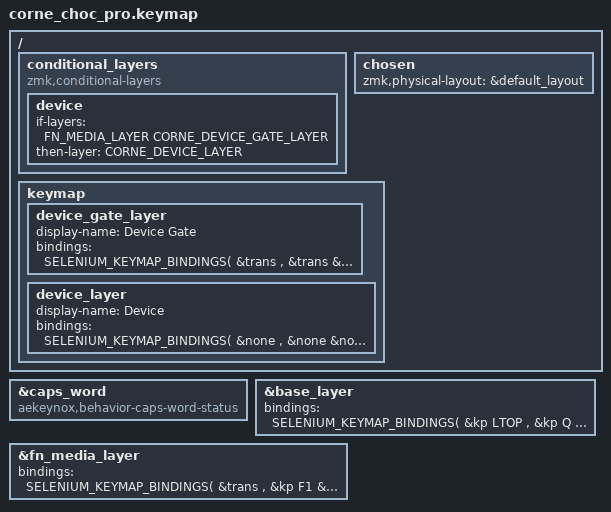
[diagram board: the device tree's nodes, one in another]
// The dual-display Corne has 42 physical keys. Keebart's shared board
// definition also supports four optional inner keys/encoders, so leave those
// logical positions disabled while mapping Selenium's 3x6+3 layout.
#define SELENIUM_KEYMAP_BINDINGS(LOUT1,  LROW1,  RROW1,  ROUT1, \
                                 LOUT2,  LROW2,  RROW2,  ROUT2, \
                                 LOUT3,  LROW3,  RROW3,  ROUT3, \
                                 LT1, LT2, LT3,  RT3, RT2, RT1) \
    LOUT1 LROW1 &none &none RROW1 ROUT1 \
    LOUT2 LROW2 &none &none RROW2 ROUT2 \
    LOUT3 LROW3             RROW3 ROUT3 \
          LT1 LT2 LT3       RT3 RT2 RT1

#include <dt-bindings/zmk/rgb.h>

// The current US QWERTY configuration uses Selenium's home-row-mod flavor.
// These two extra layers keep Bluetooth, Studio, and lighting controls behind
// the same deliberate FnMedia+T chord used by the Crosses V2 layout.
#define CORNE_DEVICE_GATE_LAYER EXTRA_LAYERS_START_INDEX
#define CORNE_DEVICE_LAYER (EXTRA_LAYERS_START_INDEX + 1)
#define HT_HOME_ROW_MODS
#include <aekeynox/selenium.keymap>

// Keebart's current HWMv1 board requires the last pre-Zephyr-4.1 ZMK. That
// release predates this optional Caps Word property; the explicit shift and
// continue lists from Aekeynox remain active without it.
&caps_word {
  compatible = "aekeynox,behavior-caps-word-status";
  /delete-property/ no-default-keys;
  /delete-property/ shift-list;
};

/ {
  conditional_layers {
    compatible = "zmk,conditional-layers";
    device {
      if-layers = <FN_MEDIA_LAYER CORNE_DEVICE_GATE_LAYER>;
      then-layer = <CORNE_DEVICE_LAYER>;
    };
  };

  chosen {
    zmk,physical-layout = &default_layout;
  };

  keymap {
    // This transparent gate has no device actions of its own. Releasing either
    // FnMedia or T exits Device and prevents accidental profile changes.
    device_gate_layer {
      display-name = "Device Gate";
      bindings = <SELENIUM_KEYMAP_BINDINGS(
        &trans , &trans &trans &trans &trans &trans , &trans &trans &trans &trans &trans , &trans ,
        &trans , &trans &trans &trans &trans &trans , &trans &trans &trans &trans &trans , &trans ,
        &trans , &trans &trans &trans &trans &trans , &trans &trans &trans &trans &trans , &trans ,
                 &trans , &trans , &trans , &trans , &trans , &trans
      )>;
    };

    device_layer {
      display-name = "Device";
      // Hold FnMedia + T with the left hand, then use only the right hand:
      // top row selects/clears Bluetooth, home row adjusts color and unlocks
      // Studio, and bottom row adjusts the RGB effect and brightness.
      bindings = <SELENIUM_KEYMAP_BINDINGS(
        &none , &none &none &none &none &trans , &bt BT_SEL 0 &bt BT_SEL 1 &bt BT_SEL 2 &bt BT_SEL 3 &bt BT_SEL 4 , &bt BT_CLR ,
        &none , &none &none &none &none &none  , &rgb_ug RGB_HUD &rgb_ug RGB_HUI &rgb_ug RGB_SAD &rgb_ug RGB_SAI &rgb_ug RGB_TOG , &studio_unlock ,
        &none , &none &none &none &none &none  , &rgb_ug RGB_EFR &rgb_ug RGB_EFF &rgb_ug RGB_BRD &rgb_ug RGB_BRI &none , &none ,
                &none , &none , &trans , &trans , &none , &none
      )>;
    };
  };
};

// Keep the dedicated punctuation keys from the 42-key Crosses layout. The
// left inner thumb returns to Selenium's Tab-tap/FnMedia-hold behavior.
&base_layer {
  bindings = <SELENIUM_KEYMAP_BINDINGS(
    &kp LTOP   ,  &kp Q  &kp W  &kp E  &kp R  &kp T   ,   &kp Y  &kp U  &kp I     &kp O   &kp P     ,  &kp MINUS  ,
    &kp LHOME  ,  &H4 A  &H3 S  &H2 D  &H1 F  &kp G   ,   &kp H  &H1 J  &H2 K     &H3 L   &H4 SEMI  ,  &kp SQT    ,
    &kp LSHIFT ,  &kp Z  &kp X  &kp C  &kp V  &kp B   ,   &kp N  &kp M  &kp COMMA &kp DOT &kp FSLH  ,  &kp RSHIFT ,
           LTHUMB_TUCK , LTHUMB_HOME , LTHUMB_REACH   ,   RTHUMB_REACH , RTHUMB_HOME , RTHUMB_TUCK
  )>;
};

// T opens the Device gate while FnMedia is held. F6 remains on S. Bootloader
// and reset use the keyboard's physical switches rather than key bindings.
&fn_media_layer {
  bindings = <SELENIUM_KEYMAP_BINDINGS(
    &trans , &kp F1 &kp F2 &kp F3 &kp F4 &mo CORNE_DEVICE_GATE_LAYER , &none &kp C_NEXT &kp C_VOL_UP &kp C_BRI_UP &kp SLCK , &trans ,
    &trans , &kp F5 &kp F6 &kp F7 &kp F8 &none , &none &UH1 C_PP &UH2 C_MUTE &UH3 C_AL_LOCK &UH4 PSCRN , &trans ,
    &trans , &kp F9 &kp F10 &kp F11 &kp F12 &none , &none &kp C_PREV &kp C_VOL_DN &kp C_BRI_DN &kp INS , &trans ,
    &trans , &trans , &trans , &trans , &trans , &none
  )>;
};
